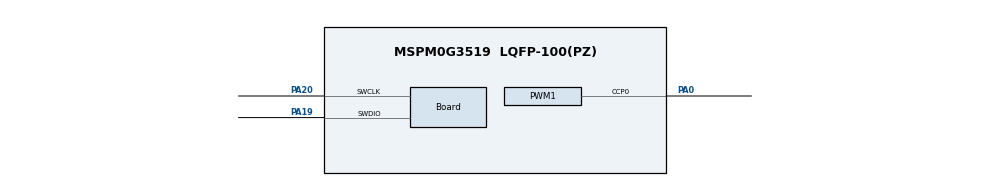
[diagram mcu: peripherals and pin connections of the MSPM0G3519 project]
//@cliArgs --device "MSPM0G351X" --package "LQFP-100(PZ)" --part "Default"
//@v2CliArgs --device "MSPM0G3519" --package "LQFP-100(PZ)"
// @cliArgs --board /ti/boards/LP_MSPM0G3519 --rtos nortos

/**
 * Import the modules used in this configuration.
 */
const PWM  = scripting.addModule("/ti/driverlib/PWM", {}, false);
const PWM1 = PWM.addInstance();

/**
 * Write custom configuration values to the imported modules.
 */
PWM1.$name                              = "PWM_1";
PWM1.ccIndex                            = [0];
PWM1.timerCount                         = 2000;
PWM1.timerStartTimer                    = true;
PWM1.interrupts                         = ["LOAD_EVENT"];
PWM1.clockDivider                       = 8;
PWM1.clockPrescale                      = 20;
PWM1.peripheral.$assign                 = "TIMA0";
PWM1.peripheral.ccp0Pin.$assign         = "PA0";
PWM1.PWM_CHANNEL_0.$name                = "ti_driverlib_pwm_PWMTimerCC2";
PWM1.PWM_CHANNEL_0.dutyCycle            = 10;

const Board                       = scripting.addModule("/ti/driverlib/Board", {}, false);
Board.peripheral.$assign          = "DEBUGSS";
Board.peripheral.swclkPin.$assign = "PA20";
Board.peripheral.swdioPin.$assign = "PA19";

const SYSCTL                 = scripting.addModule("/ti/driverlib/SYSCTL", {}, false);
SYSCTL.forceDefaultClkConfig = true;
SYSCTL.peripheral.$assign    = "SYSCTL";

const ProjectConfig              = scripting.addModule("/ti/project_config/ProjectConfig", {}, false);
ProjectConfig.migrationCondition = true;
